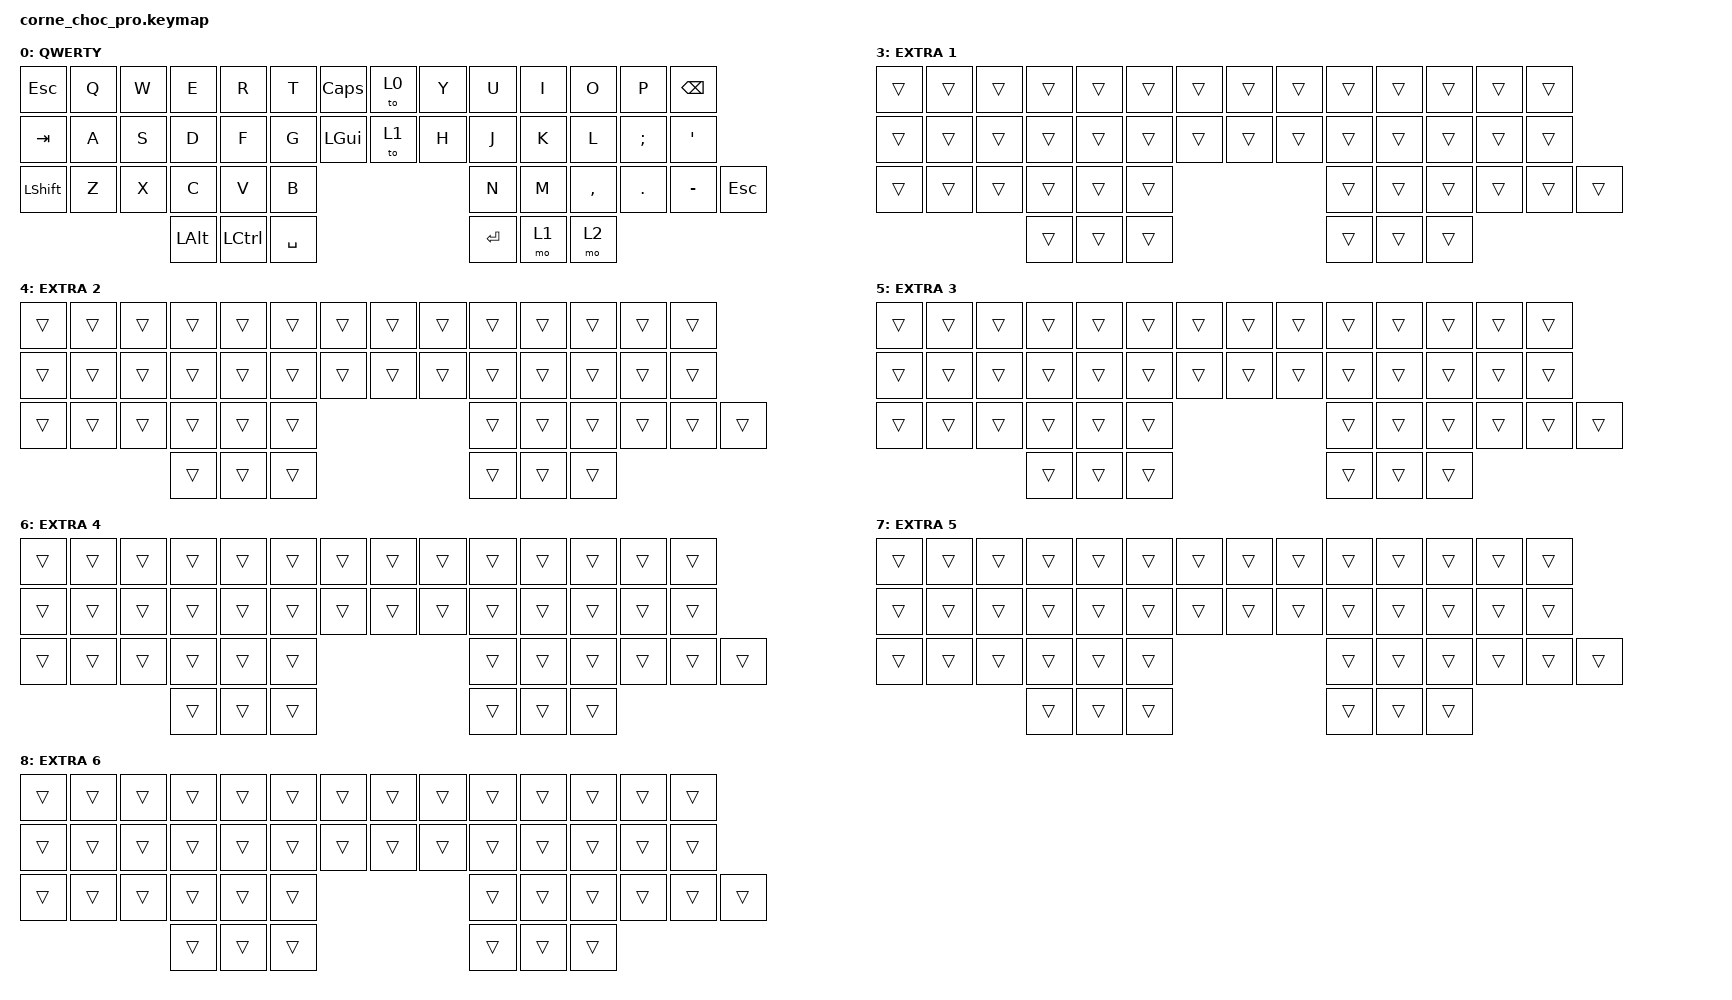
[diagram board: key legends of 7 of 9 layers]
/*
 * Copyright (c) 2020 The ZMK Contributors
 *
 * SPDX-License-Identifier: MIT
 */

#include <behaviors.dtsi>
#include <dt-bindings/zmk/keys.h>
#include <dt-bindings/zmk/bt.h>
#include <dt-bindings/zmk/rgb.h>

/ {
    chosen {
        zmk,physical-layout = &default_layout;
    };
};

/ {
    keymap {
        compatible = "zmk,keymap"; 

        default_layer {
            display-name = "QWERTY";
            // --------------------------------------------------------------------------------
            // |  ESC |  Q  |  W  |  E  |  R  |  T  |  CAPS |  0   |  Y  |  U   |  I  |  O  |  P  | BSPC |
            // | TAB |  A  |  S  |  D  |  F  |  G  |  LGUI |  1 |  H  |  J   |  K  |  L  |  ;  |  ´   |
            // | SHFT |  Z  |  X  |  C  |  V  |  B  |            |  N  |  M   |  ,  |  .  |  -  | ESC  |
            //                    | ALT | CTRL | SPC |       | ENT | 1  | 2 |
            bindings = <
                &kp ESC   &kp Q &kp W &kp E &kp R &kp T &kp CAPS   &to 0 &kp Y &kp U  &kp I     &kp O   &kp P    &kp BSPC
                &kp TAB   &kp A &kp S &kp D &kp F &kp G &kp LGUI   &to 1 &kp H &kp J  &kp K     &kp L   &kp SEMI &kp SQT
                &kp LSHFT &kp Z &kp X &kp C &kp V &kp B                     &kp N &kp M  &kp COMMA &kp DOT &kp MINUS &kp ESC
                                      &kp LALT &kp LCTRL &kp SPACE          &kp RET &mo 1 &mo 2
            >;
        };

        lower_layer {
            display-name = "NUMBER";
            // -----------------------------------------------------------------------------------------
            // |  ESC |  1  |  2  |  3  |  4  |  5   |  CAPS | 0 |  6  |  7  |  8  |  9  |  0  | BSPC |
            // | TAB | BT1 | BT2 | BT3 | BT4 | BT5   |  LGUI  | 2  |     |     |  UP |     |     |  UP  |
            // | SHFT | BTCR| RGB | RST | BOOT| Unlock|    |       |     |   LFT  |  DWN   |  RGT   |     | DWN  |
            //                    | GUI |     | SPC   |        | ENT   |     | ALT |
            bindings = <
                &kp ESC   &kp N1       &kp N2          &kp N3       &kp N4       &kp N5       &kp CAPS &to 0 &kp N6   &kp N7   &kp N8    &kp N9     &kp N0   &kp BSPC
                &kp TAB   &bt BT_SEL 0 &bt BT_SEL 1    &bt BT_SEL 2 &bt BT_SEL 3 &bt BT_SEL 4 &kp LGUI &to 2 &trans   &trans   &kp UP   &trans     &trans   &kp UP
                &kp LSHFT &bt BT_CLR   &rgb_ug RGB_TOG &sys_reset   &bootloader  &studio_unlock                  &trans   &kp LEFT &kp DOWN &kp RIGHT &trans   &kp DOWN
            >;
        };

        raise_layer {
            display-name = "SYMBOL";
            // -----------------------------------------------------------------------------------------
            // |  F1 |  F2  |  F3  |  F4  |  F5  |  nada |  nada  | F6 | F7 | F8 |  F9  |  F10  |  F11  |  F12
            // | CTRL | HUD | HUI |     |     |     |  LALT | RALT      |  -  |  =  |  (  |  )  | { |  }   |
            // | SHFT |  DOWN   |     |     |     |     |               |  *  |  +  |  <  |  >  | [ |  ]   |
            //                    | GUI |     | SPC |               | ENT |     | ALT |
            bindings = <
                &kp  F1  &kp F2  &kp F2  &kp F3  &kp F4  &kp F5  &kp LGUI  &trans   &kp F6    &kp F7    &kp F8    &kp F9     &kp F10    &kp F11 &kp F12
                &kp LCTRL &rgb_ug RGB_HUD &rgb_ug RGB_HUI &trans   &trans   &trans    &kp LALT  &kp RALT  &kp MINUS &kp EQUAL &kp LPAR  &kp RPAR &kp LBRC &kp RBRC
                &kp LSHFT &kp DOWN          &trans          &trans   &trans   &trans                        &kp ASTRK &kp PLUS  &kp NUBS  &kp LS(NUBS) &kp LBKT &kp RBKT
                                                          &kp LGUI &trans   &kp SPACE                     &kp RET   &trans    &kp RALT
            >;
        };

        extra_layer_1 {
            display-name = "EXTRA 1";
            bindings = <
                &trans &trans &trans &trans &trans &trans &trans &trans &trans &trans &trans &trans &trans &trans
                &trans &trans &trans &trans &trans &trans &trans &trans &trans &trans &trans &trans &trans &trans
                &trans &trans &trans &trans &trans &trans               &trans &trans &trans &trans &trans &trans
                                     &trans &trans &trans               &trans &trans &trans       
            >;
        };

        extra_layer_2 {
            display-name = "EXTRA 2";
            bindings = <
                &trans &trans &trans &trans &trans &trans &trans &trans &trans &trans &trans &trans &trans &trans
                &trans &trans &trans &trans &trans &trans &trans &trans &trans &trans &trans &trans &trans &trans
                &trans &trans &trans &trans &trans &trans               &trans &trans &trans &trans &trans &trans
                                     &trans &trans &trans               &trans &trans &trans           
            >;
        };

        extra_layer_3 {
            display-name = "EXTRA 3";
            bindings = <
                &trans &trans &trans &trans &trans &trans &trans &trans &trans &trans &trans &trans &trans &trans
                &trans &trans &trans &trans &trans &trans &trans &trans &trans &trans &trans &trans &trans &trans
                &trans &trans &trans &trans &trans &trans               &trans &trans &trans &trans &trans &trans
                                     &trans &trans &trans               &trans &trans &trans       
            >;
        };

        extra_layer_4 {
            display-name = "EXTRA 4";
            bindings = <
                &trans &trans &trans &trans &trans &trans &trans &trans &trans &trans &trans &trans &trans &trans
                &trans &trans &trans &trans &trans &trans &trans &trans &trans &trans &trans &trans &trans &trans
                &trans &trans &trans &trans &trans &trans               &trans &trans &trans &trans &trans &trans
                                     &trans &trans &trans               &trans &trans &trans       
            >;
        };

        extra_layer_5 {
            display-name = "EXTRA 5";
            bindings = <
                &trans &trans &trans &trans &trans &trans &trans &trans &trans &trans &trans &trans &trans &trans
                &trans &trans &trans &trans &trans &trans &trans &trans &trans &trans &trans &trans &trans &trans
                &trans &trans &trans &trans &trans &trans               &trans &trans &trans &trans &trans &trans
                                     &trans &trans &trans               &trans &trans &trans       
            >;
        };

        extra_layer_6 {
            display-name = "EXTRA 6";
            bindings = <
                &trans &trans &trans &trans &trans &trans &trans &trans &trans &trans &trans &trans &trans &trans
                &trans &trans &trans &trans &trans &trans &trans &trans &trans &trans &trans &trans &trans &trans
                &trans &trans &trans &trans &trans &trans               &trans &trans &trans &trans &trans &trans
                                     &trans &trans &trans               &trans &trans &trans       
            >;
        };
    };
};
